AUTOSAR XML (schema 4-2-1)
package /Demo/SwComponentTypes
  composition sw component type COMP_1  # Stability need for received data (see SWS RTE)
    consistency needs CN_BC
      dpg-does-not-require-coherencys:
        data prototype group CN_BC_DG1: implicit-data-access=[ASWC_B.A.A, ASWC_B.B.B, ASWC_C.A.A, ASWC_C.B.B]
      reg-requires-stabilitys:
        runnable entity group CN_BC_RG1: runnable-entity=[ASWC_B.ASWC_B_RUN1, ASWC_C.ASWC_C_RUN1]
    component ASWC_A: type=ASWC_A
    component ASWC_B: type=ASWC_B
    component ASWC_C: type=ASWC_C
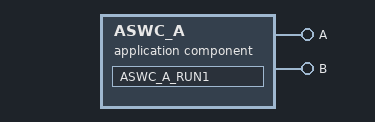
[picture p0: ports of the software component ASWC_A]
  application sw component type ASWC_A
    provide port A: provided-interface=A
    provide port B: provided-interface=B
    behavior IB_ASWC_A
      runnable ASWC_A_RUN1
        data-write-access:
          access DWP_ASWC_A_RUN1_A_A: accessed-variable=A.A
          access DWP_ASWC_A_RUN1_B_B: accessed-variable=B.B
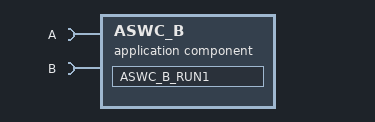
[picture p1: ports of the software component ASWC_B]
  application sw component type ASWC_B
    require port A: required-interface=A
    require port B: required-interface=B
    behavior IB_ASWC_B
      runnable ASWC_B_RUN1
        data-read-access:
          access DWP_ASWC_B_RUN1_A_A: accessed-variable=A.A
          access DWP_ASWC_B_RUN1_B_B: accessed-variable=B.B
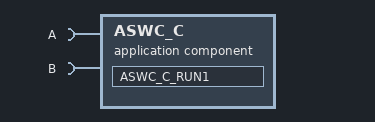
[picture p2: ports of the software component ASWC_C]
  application sw component type ASWC_C
    require port A: required-interface=A
    require port B: required-interface=B
    behavior IB_ASWC_C
      runnable ASWC_C_RUN1
        data-read-access:
          access DWP_ASWC_C_RUN1_A_A: accessed-variable=A.A
          access DWP_ASWC_C_RUN1_B_B: accessed-variable=B.B
package /Demo/PortInterfaces
  sender receiver interface A
    data A
  sender receiver interface B
    data B
